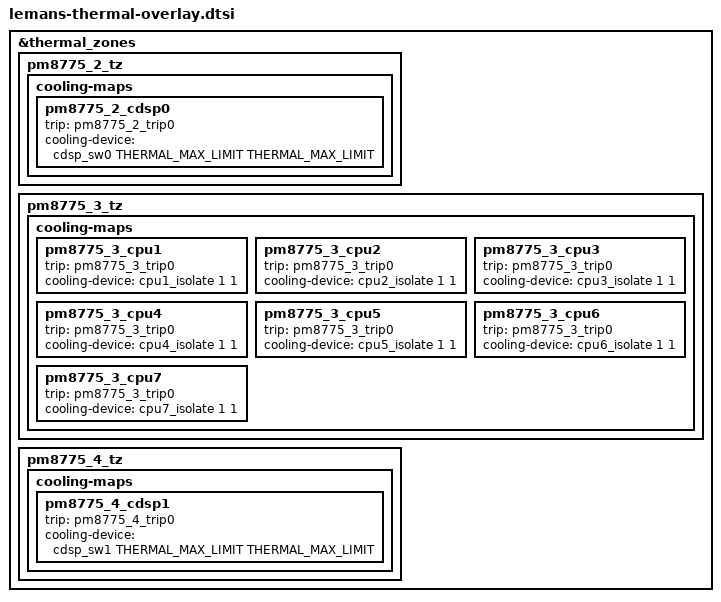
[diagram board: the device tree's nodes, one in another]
#include <dt-bindings/thermal/thermal_qti.h>

&thermal_zones {
	pm8775_2_tz {
		cooling-maps {
			pm8775_2_cdsp0 {
				trip = <&pm8775_2_trip0>;
				cooling-device = <&cdsp_sw0 THERMAL_MAX_LIMIT
							THERMAL_MAX_LIMIT>;
			};
		};
	};

	pm8775_3_tz {
		cooling-maps {
			pm8775_3_cpu1 {
				trip = <&pm8775_3_trip0>;
				cooling-device = <&cpu1_isolate 1 1>;
			};

			pm8775_3_cpu2 {
				trip = <&pm8775_3_trip0>;
				cooling-device = <&cpu2_isolate 1 1>;
			};

			pm8775_3_cpu3 {
				trip = <&pm8775_3_trip0>;
				cooling-device = <&cpu3_isolate 1 1>;
			};

			pm8775_3_cpu4 {
				trip = <&pm8775_3_trip0>;
				cooling-device = <&cpu4_isolate 1 1>;
			};

			pm8775_3_cpu5 {
				trip = <&pm8775_3_trip0>;
				cooling-device = <&cpu5_isolate 1 1>;
			};

			pm8775_3_cpu6 {
				trip = <&pm8775_3_trip0>;
				cooling-device = <&cpu6_isolate 1 1>;
			};

			pm8775_3_cpu7 {
				trip = <&pm8775_3_trip0>;
				cooling-device = <&cpu7_isolate 1 1>;
			};
		};
	};

	pm8775_4_tz {
		cooling-maps {
			pm8775_4_cdsp1 {
				trip = <&pm8775_4_trip0>;
				cooling-device = <&cdsp_sw1 THERMAL_MAX_LIMIT
							THERMAL_MAX_LIMIT>;
			};
		};
	};
};
